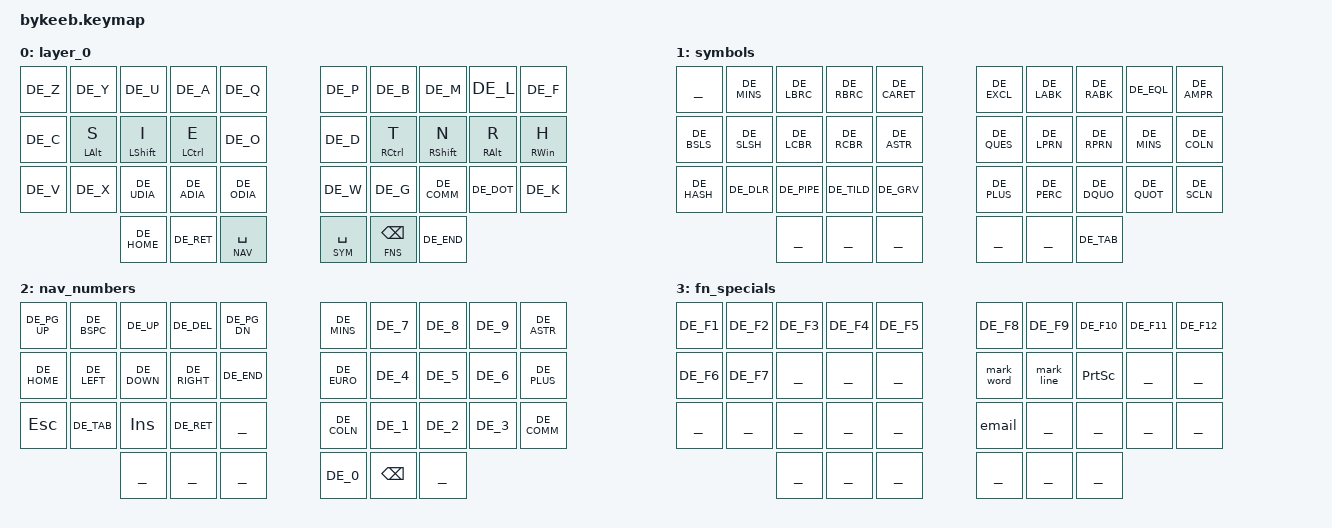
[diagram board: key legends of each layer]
#include <behaviors.dtsi>
#include <dt-bindings/zmk/keys.h>
#include <dt-bindings/zmk/bt.h>

#include "keymap_german_mac_iso_zmk.h"
#define DEFAULT 0
#define SYM     1
#define NAV     2
#define FNS     3

/ {
    macros {
        mark_word: MarkWork {
            compatible = "zmk,behavior-macro";
            #binding-cells = <0>;
            bindings =
                <&macro_press>,
                <&kp LCTRL>,
                <&macro_tap>,
                <&kp LEFT>,
                <&macro_release>,
                <&macro_press>,
                <&kp LCTRL &kp LSHFT>,
                <&macro_tap>,
                <&kp RIGHT_ARROW>,
                <&macro_release>;

            label = "MARKWORK";
        };

        mark_line: mark_line {
            compatible = "zmk,behavior-macro";
            #binding-cells = <0>;
            bindings =
                <&macro_press>,
                <&kp LCTRL>,
                <&macro_tap>,
                <&kp HOME>,
                <&macro_release>,
                <&macro_press>,
                <&kp LCTRL &kp LSHFT>,
                <&macro_tap>,
                <&kp END>,
                <&macro_release>;

            label = "MARK_LINE";
        };

        email: email {
            compatible = "zmk,behavior-macro";
            #binding-cells = <0>;
            bindings = <&kp T &kp H &kp O &kp M &kp A &kp S &kp DOT &kp M &kp A &kp N &kp G &kp AT &kp I &kp T &kp MINUS &kp K &kp R &kp U &kp E &kp G &kp E &kp R &kp DOT &kp D &kp E>;
            label = "EMAIL";
        };
    };

    behaviors {
        hm: homerow_mods {
            compatible = "zmk,behavior-hold-tap";
            label = "HomerowMods";
            bindings = <&kp>, <&kp>;

            #binding-cells = <2>;
            tapping-term-ms = <200>;
            flavor = "tap-preferred";
        };

        hs: homerow_shift {
            compatible = "zmk,behavior-hold-tap";

            label = "HomerowShift";
            #binding-cells = <2>;
            tapping-term-ms = <175>;
            flavor = "balanced";
            bindings = <&kp>, <&kp>;
        };
    };

    keymap {
        compatible = "zmk,keymap";

        layer_0 {
// -----------------------------------------------------------------------------------------
// |  Z  |  Y  |  U  |  A  |  Q  |   |  P  |  B   |  M  |  O  |  F  |
// |  C  |  S  |  I  |  E  |  O  |   |  D  |  T   |  N  |  L  |  H  |
// |  V  |  X  |  Ü  |  Ä  |  Ö  |   |  W  |  G   |  ,  |  .  |  K  |
//             | HOME | RET | SPC |   | SPC | BSP  | END |
            bindings = <
  DE_Z  DE_Y        DE_U           DE_A                DE_Q       DE_P        DE_B            DE_M         DE_L        DE_F
  DE_C  &hm LALT S  &hs LSHFT I    &hm LEFT_CONTROL E  DE_O       DE_D        &hm RCTRL T     &hs RSHFT N  &hm RALT R  &hm RWIN H
  DE_V  DE_X        DE_UDIA        DE_ADIA             DE_ODIA    DE_W        DE_G            DE_COMM      DE_DOT      DE_K
                     DE_HOME          DE_RET   &lt NAV SPACE        &lt SYM SPACE  &lt FNS BACKSPACE  DE_END
            >;
        };

        symbols {
// -----------------------------------------------------------------------------------------
// |     |  _  |  [  |  ]  |  ^  |   |  !  |  <   |  >  |  =  |  &  |
// |  BSL|  /  |  {  |  }  |  *  |   |  ?  |  (   |  )  |  -  |  :  |
// |  #  |  $  |  |  |  ~  |  ´  |   |  +  |  %   |  "  |  '  |  ;  |
//             |  |  |  |   |  |   | TAB |
            bindings = <
  ___            DE_MINS       DE_LBRC           DE_RBRC        DE_CARET    DE_EXCL       DE_LABK     DE_RABK       DE_EQL          DE_AMPR
  DE_BSLS        DE_SLSH       DE_LCBR           DE_RCBR        DE_ASTR     DE_QUES       DE_LPRN     DE_RPRN       DE_MINS         DE_COLN
  DE_HASH        DE_DLR        DE_PIPE           DE_TILD        DE_GRV      DE_PLUS       DE_PERC     DE_DQUO       DE_QUOT         DE_SCLN
                                       ___                 ___            ___          ___            ___          DE_TAB
            >;
        };

        nav_numbers {
// -----------------------------------------------------------------------------------------
// |  PGUP  |  BSP  |  UP   |  DEL  |  PGDOW  |   |  -  |  7   |  8  |  9  |  *  |
// |  HOME  |  LEF  |  DOW  |  RIG  |  END  |   |  €  |  4   |  5  |  6  |  +  |
// |  ESC   |  TAB  |  INS  |  END  |    |   |  :  |  1   |  2  |  3  |  ,  |
//             |  |  |  |   | 0 | BSP  |  |
            bindings = <
  DE_PG_UP   DE_BSPC  DE_UP    DE_DEL    DE_PG_DN    DE_MINS      DE_7    DE_8  DE_9  DE_ASTR
  DE_HOME    DE_LEFT  DE_DOWN  DE_RIGHT  DE_END      DE_EURO      DE_4    DE_5  DE_6  DE_PLUS
  &kp ESC    DE_TAB   &kp INS  DE_RET    ___         DE_COLN      DE_1    DE_2  DE_3  DE_COMM
                       ___    ___     ___       DE_0          &kp BSPC  ___
            >;
        };

        fn_specials {
// -----------------------------------------------------------------------------------------
// |  F1  |  F2  |  F3   |  F4  |  F5  |   |  F8     |  F9      |  F10         |  F11 |  F12  |
// |  F6  |  F7  |       |      |      |   |  mword  |  mline   |  screenshot  |      |       |
// |      |      |       |      |      |   |  email  |          |              |      |       |
//             |  |  |  |   |  | BSP  |  |
            bindings = <
  DE_F1  DE_F2  DE_F3  DE_F4  DE_F5    DE_F8      DE_F9     DE_F10          DE_F11  DE_F12
  DE_F6  DE_F7  ___  ___  ___    &mark_word  &mark_line  &kp PRINTSCREEN  ___   ___
  ___  ___  ___  ___  ___    &email      ___      ___           ___   ___
                  ___  ___  ___    ___      ___      ___
            >;
        };
    };
};
